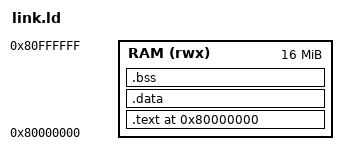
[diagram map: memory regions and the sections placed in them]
ENTRY(_start)

MEMORY
{
    RAM (rwx) : ORIGIN = 0x80000000, LENGTH = 0x01000000
}

SECTIONS
{
    . = ORIGIN(RAM);

    .text : {
        *(.text.start)
        *(.text*)
        *(.rodata*)
    } > RAM

    .data : {
        *(.data*)
    } > RAM

    .bss (NOLOAD) : {
        . = ALIGN(16);
        __bss_start = .;
        *(.bss*)
        *(COMMON)
        . = ALIGN(16);
        __bss_end = .;
    } > RAM

    . = ALIGN(16);
    __stack_top = ORIGIN(RAM) + LENGTH(RAM) - 16;
}
